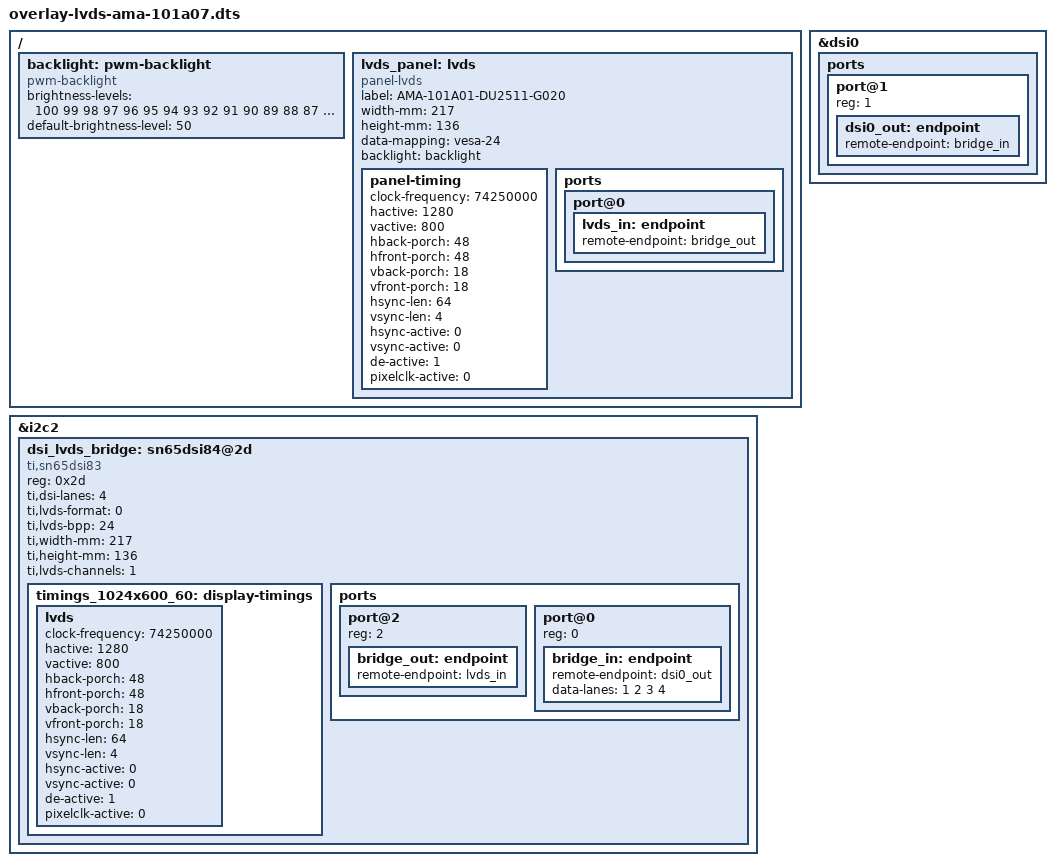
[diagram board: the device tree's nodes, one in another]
/*
 * Copyright (C) 2022 Avnet Embedded GmbH
 *
 * This program is free software; you can redistribute it and/or
 * modify it under the terms of the GNU General Public License as
 * published by the Free Software Foundation version 2.
 *
 * This program is distributed "as is" WITHOUT ANY WARRANTY of any
 * kind, whether express or implied; without even the implied warranty
 * of MERCHANTABILITY or FITNESS FOR A PARTICULAR PURPOSE.  See the
 * GNU General Public License for more details.
 */

/dts-v1/;
/plugin/;

/ {
       
       fragment@4000 {
               target-path = "/";
               __overlay__ {
	               backlight: pwm-backlight {
		       		compatible = "pwm-backlight";                      
        			//pwms = <&mtu3 0 500000>;                         
			        brightness-levels = <100 99 98 97 96 95 94 93 92 91
			                90 89 88 87 86 85 84 83 82 81              
			                80 79 78 77 76 75 74 73 72 71              
			                70 69 68 67 66 65 64 63 62 61              
			                60 59 58 57 56 55 54 53 52 51              
			                50 49 48 47 46 45 44 43 42 41              
			                40 39 38 37 36 35 34 33 32 31              
			                30 29 28 27 26 25 24 23 22 21              
			                20 19 18 17 16 15 14 13 12 11              
			                10  9  8  7  6  5  4  3  2  1              
			                 0>;                                       
			        default-brightness-level = <50>;                   
			        status = "okay";                                   
                       };
	       };
       };
       
       fragment@4001 {
               target-path = "/";
               __overlay__ {
	       		lvds_panel: lvds {                                              
		        compatible = "panel-lvds";                              
		        label = "AMA-101A01-DU2511-G020";                       
		        width-mm = <217>;                                       
		        height-mm = <136>;                                      
		        data-mapping = "vesa-24";                               
		        backlight = <&backlight>;                               
		        status = "okay";                                        
		                                                                
		        	panel-timing {                                          
		        	    clock-frequency = <74250000>;                       
		        	    hactive = <1280>;                                   
		        	    vactive = <800>;                                    
		        	    hback-porch = <48>;                                 
		        	    hfront-porch = <48>;                                
		        	    vback-porch = <18>;                                 
		        	    vfront-porch = <18>;                                
		        	    hsync-len = <64>;                                   
		        	    vsync-len = <4>;                                    
		        	    hsync-active = <0>;                                 
		        	    vsync-active = <0>;                                 
		        	    de-active = <1>;                                    
		        	    pixelclk-active = <0>;                              
		        	};                                                      
		        	                                                        
		        	ports {                                                 
		        	        port@0 {                                        
		        	                lvds_in: endpoint {                     
		        	                        remote-endpoint = <&bridge_out>;
		        	                };                                      
		        	        };                                              
		        	};                                                      
			};
	       };
       };

	fragment@4002 {
                target = <&dsi0>;
                __overlay__ {
			status = "okay";                                                       
			ports {                                                
			        port@1 {                                       
			                reg = <1>;                             
			                dsi0_out: endpoint {                   
			                        remote-endpoint = <&bridge_in>;
			                };                                     
			        };                                             
			};                                                     
                };
        };

	fragment@4003 {
                target = <&i2c2>;
                __overlay__ {
			dsi_lvds_bridge: sn65dsi84@2d {
        		        compatible = "ti,sn65dsi83";
        		        reg = <0x2d>;
        		        ti,dsi-lanes = <4>;
        		        ti,lvds-format = <0>;
        		        ti,lvds-bpp = <24>;
        		        ti,width-mm = <217>;
        		        ti,height-mm = <136>;
				ti,lvds-channels = <1>;
        		        //enable-gpios = <&exp1 10 GPIO_ACTIVE_HIGH>;
				//enable-panel-gpios = <&pinctrl RZG2L_GPIO(1, 1) GPIO_ACTIVE_HIGH>;
				//ti,dsi-mode-flags = <0x401>;
        		        status = "okay";

        		        timings_1024x600_60:display-timings {
					lvds {
						clock-frequency = <74250000>;
						hactive = <1280>;
						vactive = <800>;
						hback-porch = <48>;
						hfront-porch = <48>;
						vback-porch = <18>;
						vfront-porch = <18>;
						hsync-len = <64>;
						vsync-len = <4>;
						hsync-active = <0>;
						vsync-active = <0>;
						de-active = <1>;
						pixelclk-active = <0>;
					};
				};

				ports{
					#address-cells = <1>;
					#size-cells = <0>;

					port@2 {
                                                reg = <2>;
                                                bridge_out: endpoint {
                                                        remote-endpoint = <&lvds_in>;
                                                };
                                        };

					port@0 {
						reg = <0>;
						bridge_in: endpoint {
							remote-endpoint = <&dsi0_out>;
							data-lanes = <1 2 3 4>;
						};
					};
        			};
			};
		};
	};
};

